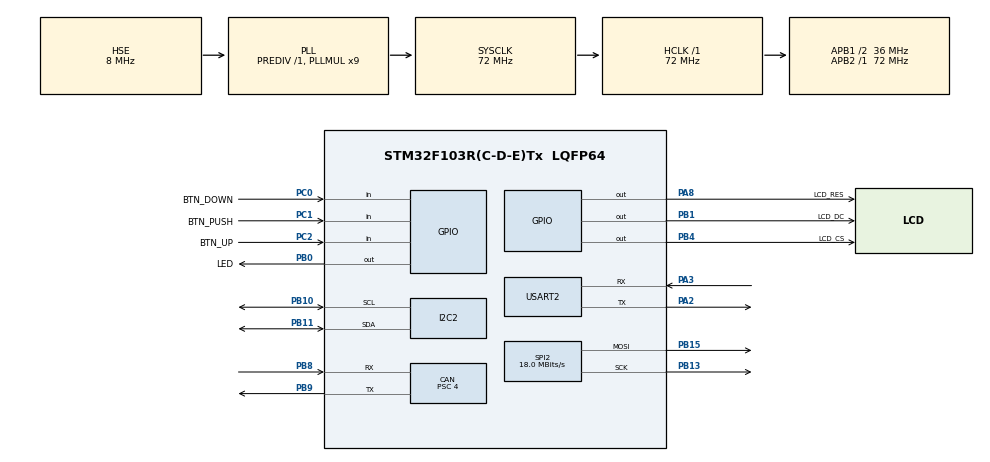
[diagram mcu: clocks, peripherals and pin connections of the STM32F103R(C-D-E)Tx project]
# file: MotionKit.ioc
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CAN.BS1=CAN_BS1_7TQ
CAN.CalculateBaudRate=1000000
CAN.CalculateTimeBit=1000
CAN.CalculateTimeQuantum=111.11111111111111
CAN.Prescaler=4
Dma.Request0=SPI2_TX
Dma.Request1=USART2_RX
Dma.Request2=USART2_TX
Dma.SPI2_TX.0.Direction=DMA_MEMORY_TO_PERIPH
Dma.SPI2_TX.0.Instance=DMA1_Channel5
Dma.SPI2_TX.0.MemDataAlignment=DMA_MDATAALIGN_BYTE
Dma.SPI2_TX.0.MemInc=DMA_MINC_ENABLE
Dma.SPI2_TX.0.Mode=DMA_NORMAL
Dma.SPI2_TX.0.PeriphDataAlignment=DMA_PDATAALIGN_BYTE
Dma.SPI2_TX.0.PeriphInc=DMA_PINC_DISABLE
Dma.SPI2_TX.0.Priority=DMA_PRIORITY_LOW
Dma.USART2_RX.1.Direction=DMA_PERIPH_TO_MEMORY
Dma.USART2_RX.1.Instance=DMA1_Channel6
Dma.USART2_RX.1.MemDataAlignment=DMA_MDATAALIGN_BYTE
Dma.USART2_RX.1.MemInc=DMA_MINC_ENABLE
Dma.USART2_RX.1.Mode=DMA_NORMAL
Dma.USART2_RX.1.PeriphDataAlignment=DMA_PDATAALIGN_BYTE
Dma.USART2_RX.1.PeriphInc=DMA_PINC_DISABLE
Dma.USART2_RX.1.Priority=DMA_PRIORITY_LOW
Dma.USART2_TX.2.Direction=DMA_MEMORY_TO_PERIPH
Dma.USART2_TX.2.Instance=DMA1_Channel7
Dma.USART2_TX.2.MemDataAlignment=DMA_MDATAALIGN_BYTE
Dma.USART2_TX.2.MemInc=DMA_MINC_ENABLE
Dma.USART2_TX.2.Mode=DMA_NORMAL
Dma.USART2_TX.2.PeriphDataAlignment=DMA_PDATAALIGN_BYTE
Dma.USART2_TX.2.PeriphInc=DMA_PINC_DISABLE
Dma.USART2_TX.2.Priority=DMA_PRIORITY_LOW
FREERTOS.Tasks01=defaultTask,24,128,StartDefaultTask,Default,NULL,Dynamic,NULL,NULL;DisplayTask,39,3200,StartDisplayTask,As weak,NULL,Dynamic,NULL,NULL;ConnectionTask,8,128,StartConnectionTask,As weak,NULL,Dynamic,NULL,NULL;MotionTask,55,256,StartMotionTask,As weak,NULL,Dynamic,NULL,NULL
FREERTOS.configTOTAL_HEAP_SIZE=20000
FREERTOS.configUSE_NEWLIB_REENTRANT=1
Mcu.Family=STM32F1
Mcu.Name=STM32F103R(C-D-E)Tx
Mcu.Package=LQFP64
NVIC.DMA1_Channel5_IRQn=true\:5\:0\:false\:false\:true\:true\:false\:true\:true
NVIC.DMA1_Channel6_IRQn=true\:5\:0\:false\:false\:true\:true\:false\:true\:true
NVIC.DMA1_Channel7_IRQn=true\:5\:0\:false\:false\:true\:true\:false\:true\:true
NVIC.PriorityGroup=NVIC_PRIORITYGROUP_4
NVIC.TIM7_IRQn=true\:15\:0\:false\:false\:true\:false\:false\:true\:true
NVIC.TimeBase=TIM7_IRQn
NVIC.TimeBaseIP=TIM7
NVIC.USART2_IRQn=true\:5\:0\:false\:false\:true\:true\:true\:true\:true
PA13.Mode=Serial_Wire
PA13.Signal=SYS_JTMS-SWDIO
PA14.Mode=Serial_Wire
PA14.Signal=SYS_JTCK-SWCLK
PA2.Mode=Asynchronous
PA2.Signal=USART2_TX
PA3.Mode=Asynchronous
PA3.Signal=USART2_RX
PA8.GPIO_Label=LCD_RES
PA8.Signal=GPIO_Output
PB0.GPIO_Label=LED
PB0.Signal=GPIO_Output
PB1.GPIO_Label=LCD_DC
PB1.Signal=GPIO_Output
PB10.Mode=I2C
PB10.Signal=I2C2_SCL
PB11.Mode=I2C
PB11.Signal=I2C2_SDA
PB13.Mode=TX_Only_Simplex_Unidirect_Master
PB13.Signal=SPI2_SCK
PB15.Mode=TX_Only_Simplex_Unidirect_Master
PB15.Signal=SPI2_MOSI
PB4.GPIO_Label=LCD_CS
PB4.Signal=GPIO_Output
PB8.Mode=CAN_Activate
PB8.Signal=CAN_RX
PB9.Mode=CAN_Activate
PB9.Signal=CAN_TX
PC0.GPIO_Label=BTN_DOWN
PC0.Signal=GPIO_Input
PC1.GPIO_Label=BTN_PUSH
PC1.Signal=GPIO_Input
PC14-OSC32_IN.Mode=LSE-External-Oscillator
PC14-OSC32_IN.Signal=RCC_OSC32_IN
PC15-OSC32_OUT.Mode=LSE-External-Oscillator
PC15-OSC32_OUT.Signal=RCC_OSC32_OUT
PC2.GPIO_Label=BTN_UP
PC2.Signal=GPIO_Input
PD0-OSC_IN.Mode=HSE-External-Oscillator
PD0-OSC_IN.Signal=RCC_OSC_IN
PD1-OSC_OUT.Mode=HSE-External-Oscillator
PD1-OSC_OUT.Signal=RCC_OSC_OUT
ProjectManager.HeapSize=0x200
ProjectManager.StackSize=0x400
ProjectManager.TargetToolchain=STM32CubeIDE
RCC.AHBFreq_Value=72000000
RCC.APB1CLKDivider=RCC_HCLK_DIV2
RCC.APB1Freq_Value=36000000
RCC.APB1TimFreq_Value=72000000
RCC.APB2Freq_Value=72000000
RCC.APB2TimFreq_Value=72000000
RCC.HCLKFreq_Value=72000000
RCC.PLLMUL=RCC_PLL_MUL9
RCC.PLLSourceVirtual=RCC_PLLSOURCE_HSE
RCC.SYSCLKFreq_VALUE=72000000
RCC.SYSCLKSource=RCC_SYSCLKSOURCE_PLLCLK
RCC.USBFreq_Value=72000000
SPI2.BaudRatePrescaler=SPI_BAUDRATEPRESCALER_2
SPI2.CLKPhase=SPI_PHASE_2EDGE
SPI2.CLKPolarity=SPI_POLARITY_HIGH
SPI2.CalculateBaudRate=18.0 MBits/s
SPI2.Direction=SPI_DIRECTION_2LINES
SPI2.Mode=SPI_MODE_MASTER
SPI2.VirtualType=VM_MASTER
USART2.VirtualMode=VM_ASYNC
VP_FREERTOS_VS_CMSIS_V2.Mode=CMSIS_V2
VP_SYS_VS_tim7.Mode=TIM7
board=custom

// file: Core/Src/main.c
/* USER CODE BEGIN Header */
/**
  ******************************************************************************
  * @file           : main.c
  * @brief          : Main program body
  ******************************************************************************
  * @attention
  *
  * Copyright (c) 2024 STMicroelectronics.
  * All rights reserved.
  *
  * This software is licensed under terms that can be found in the LICENSE file
  * in the root directory of this software component.
  * If no LICENSE file comes with this software, it is provided AS-IS.
  *
  ******************************************************************************
  */
/* USER CODE END Header */
#include "main.h"
#include "cmsis_os.h"
#include "can.h"
#include "dma.h"
#include "i2c.h"
#include "spi.h"
#include "usart.h"
#include "gpio.h"

void SystemClock_Config(void);
void MX_FREERTOS_Init(void);

int main(void)
{

  /* MCU Configuration--------------------------------------------------------*/

  /* Reset of all peripherals, Initializes the Flash interface and the Systick. */
  HAL_Init();

  /* Configure the system clock */
  SystemClock_Config();

  /* Initialize all configured peripherals */
  MX_GPIO_Init();
  MX_DMA_Init();
  MX_CAN_Init();
  MX_SPI2_Init();
  MX_I2C2_Init();
  MX_USART2_UART_Init();

  /* Init scheduler */
  osKernelInitialize();

  /* Call init function for freertos objects (in freertos.c) */
  MX_FREERTOS_Init();

  /* Start scheduler */
  osKernelStart();

  /* We should never get here as control is now taken by the scheduler */
  /* Infinite loop */
  while (1)
  {

  }
}

void SystemClock_Config(void)
{
  RCC_OscInitTypeDef RCC_OscInitStruct = {0};
  RCC_ClkInitTypeDef RCC_ClkInitStruct = {0};

  /** Initializes the RCC Oscillators according to the specified parameters
  * in the RCC_OscInitTypeDef structure.
  */
  RCC_OscInitStruct.OscillatorType = RCC_OSCILLATORTYPE_HSE;
  RCC_OscInitStruct.HSEState = RCC_HSE_ON;
  RCC_OscInitStruct.HSEPredivValue = RCC_HSE_PREDIV_DIV1;
  RCC_OscInitStruct.HSIState = RCC_HSI_ON;
  RCC_OscInitStruct.PLL.PLLState = RCC_PLL_ON;
  RCC_OscInitStruct.PLL.PLLSource = RCC_PLLSOURCE_HSE;
  RCC_OscInitStruct.PLL.PLLMUL = RCC_PLL_MUL9;
  if (HAL_RCC_OscConfig(&RCC_OscInitStruct) != HAL_OK)
  {
    Error_Handler();
  }

  /** Initializes the CPU, AHB and APB buses clocks
  */
  RCC_ClkInitStruct.ClockType = RCC_CLOCKTYPE_HCLK|RCC_CLOCKTYPE_SYSCLK
                              |RCC_CLOCKTYPE_PCLK1|RCC_CLOCKTYPE_PCLK2;
  RCC_ClkInitStruct.SYSCLKSource = RCC_SYSCLKSOURCE_PLLCLK;
  RCC_ClkInitStruct.AHBCLKDivider = RCC_SYSCLK_DIV1;
  RCC_ClkInitStruct.APB1CLKDivider = RCC_HCLK_DIV2;
  RCC_ClkInitStruct.APB2CLKDivider = RCC_HCLK_DIV1;

  if (HAL_RCC_ClockConfig(&RCC_ClkInitStruct, FLASH_LATENCY_2) != HAL_OK)
  {
    Error_Handler();
  }
}

void HAL_TIM_PeriodElapsedCallback(TIM_HandleTypeDef *htim)
{
  if (htim->Instance == TIM7) {
    HAL_IncTick();
  }
}

void Error_Handler(void)
{
  __disable_irq();
  while (1)
  {
  }
}

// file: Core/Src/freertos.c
/* USER CODE BEGIN Header */
/**
  ******************************************************************************
  * File Name          : freertos.c
  * Description        : Code for freertos applications
  ******************************************************************************
  * @attention
  *
  * Copyright (c) 2024 STMicroelectronics.
  * All rights reserved.
  *
  * This software is licensed under terms that can be found in the LICENSE file
  * in the root directory of this software component.
  * If no LICENSE file comes with this software, it is provided AS-IS.
  *
  ******************************************************************************
  */
/* USER CODE END Header */

#include "FreeRTOS.h"
#include "task.h"
#include "main.h"
#include "cmsis_os.h"

/* USER CODE BEGIN Includes */
//#include "can.h"
#include "App/Display.h"
//#include <string.h>
#include <stdio.h>
#include "PancakeConfig.h"
#include "Drv/LCD.h"
#include "App/Motion.h"
#include "App/Connection.h"
//#include "App/LVGL_UI/ui.h"
//#include "Drv/NodeMotor.h"
/* USER CODE END Includes */

/* USER CODE BEGIN Variables */
//uint8_t status = 0;
MotionType PancakeMotion;
//extern uint8_t bufByte;
/* USER CODE END Variables */
/* Definitions for defaultTask */
osThreadId_t defaultTaskHandle;
const osThreadAttr_t defaultTask_attributes = {
  .name = "defaultTask",
  .stack_size = 128 * 4,
  .priority = (osPriority_t) osPriorityNormal,
};
/* Definitions for DisplayTask */
osThreadId_t DisplayTaskHandle;
const osThreadAttr_t DisplayTask_attributes = {
  .name = "DisplayTask",
  .stack_size = 3200 * 4,
  .priority = (osPriority_t) osPriorityAboveNormal7,
};
/* Definitions for ConnectionTask */
osThreadId_t ConnectionTaskHandle;
const osThreadAttr_t ConnectionTask_attributes = {
  .name = "ConnectionTask",
  .stack_size = 128 * 4,
  .priority = (osPriority_t) osPriorityLow,
};
/* Definitions for MotionTask */
osThreadId_t MotionTaskHandle;
const osThreadAttr_t MotionTask_attributes = {
  .name = "MotionTask",
  .stack_size = 256 * 4,
  .priority = (osPriority_t) osPriorityRealtime7,
};

void StartDefaultTask(void *argument);
void StartDisplayTask(void *argument);
void StartConnectionTask(void *argument);
void StartMotionTask(void *argument);

void MX_FREERTOS_Init(void); /* (MISRA C 2004 rule 8.1) */

void MX_FREERTOS_Init(void) {

  /* Create the thread(s) */
  /* creation of defaultTask */
  defaultTaskHandle = osThreadNew(StartDefaultTask, NULL, &defaultTask_attributes);

  /* creation of DisplayTask */
  DisplayTaskHandle = osThreadNew(StartDisplayTask, NULL, &DisplayTask_attributes);

  /* creation of ConnectionTask */
  ConnectionTaskHandle = osThreadNew(StartConnectionTask, NULL, &ConnectionTask_attributes);

  /* creation of MotionTask */
  MotionTaskHandle = osThreadNew(StartMotionTask, NULL, &MotionTask_attributes);

}

__weak void StartDefaultTask(void *argument)
{
  /* USER CODE BEGIN StartDefaultTask */
  /* Infinite loop */
  for(;;)
  {
      HAL_GPIO_TogglePin(GPIOB, GPIO_PIN_0);
//      HAL_UART_Transmit(&huart2,"HELLO\n",6,HAL_MAX_DELAY);

      osDelay(1000);
  }
  /* USER CODE END StartDefaultTask */
}

__weak void StartDisplayTask(void *argument)
{
}

__weak void StartConnectionTask(void *argument)
{
  for(;;)
  {
    osDelay(1);
  }
}

__weak void StartMotionTask(void *argument)
{
}
